# KM1M7CF14 register map
Vendor: Nuvoton Technology Corporation Japan; Series: KM1M7CF; File version: 1.0.3
CPU: CM7 r1p2, little endian, MPU, FPU, double-precision FPU, I-cache, D-cache, ITCM, DTCM, 4 interrupt priority bits
Registers are 32-bit, read-write, no defined reset value unless marked. A register's access mark holds for its fields unless they carry their own. Offsets are from the block's base; [hi:lo] are bit positions; {n}, {i} and the like mark numbered series; 'fields as' and 'values as' point back to an identical list.

## SIF23456 — Serial Interface 2-6
Base 0x40050200
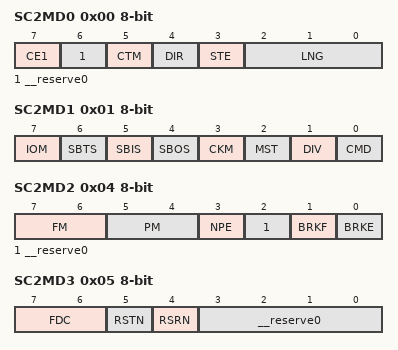
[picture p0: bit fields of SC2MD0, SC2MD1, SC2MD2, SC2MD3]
0x00 SC2MD0 8-bit — Serial 2 Mode Register 0
  [7] CE1 — Clock polarity selection [Clock-Synchronous]
  [6] __reserve0 — This bit must be set to "0".
  [5] CTM — Continuous communication mode selection [Clock-Synchronous]
  [4] DIR — Transfer first bit selection
  [3] STE — Start condition selection [Clock-Synchronous] (*1)
  [2:0] LNG — Transfer bit count [Clock-Synchronous] (*2)
0x01 SC2MD1 8-bit — Serial 2 Mode Register 1
  [7] IOM — Data input pin selection
  [6] SBTS — SBTn pin control
  [5] SBIS — SBIn(RXDn)/SBOn(TXDn) pin input control
  [4] SBOS — SBOn(TXDn) pin output control
  [3] CKM — Division selection of transfer clock [Clock-Synchronous]
  [2] MST — Master/salve communication selection [Clock-Synchronous]
  [1] DIV — Division value selection of transfer clock (*1)
  [0] CMD — Communication mode selection
0x04 SC2MD2 8-bit access per field — Serial 2 Mode Register 2
  [7:6] FM rw — The number of character bit and stop bit selection [UART]
  [5:4] PM rw — Parity bit function selection [UART]
  [3] NPE rw — Parity bit selection [UART]
  [2] __reserve0 rw — This bit must be set to "0".
  [1] BRKF ro — Break reception detection [UART]
  [0] BRKE rw — Break transmission control [UART]
0x05 SC2MD3 8-bit access per field — Serial 2 Mode Register 3
  [7:6] FDC rw — Output level selection after the final bit transmit (SBOn pin) [Clock-Synchronous]
  [5] RSTN rw — [Clock-Synchronous]
  [4] RSRN rw — [Clock-Synchronous]
  [3:0] __reserve0 ro — "0" is always read out.
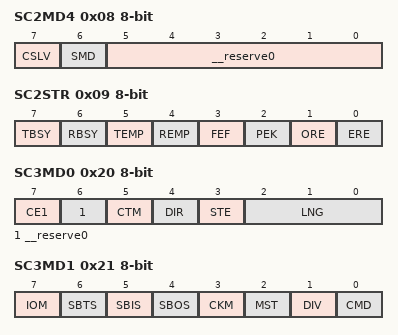
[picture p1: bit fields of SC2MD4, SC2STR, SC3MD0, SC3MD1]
0x08 SC2MD4 8-bit access per field — Serial 2 Mode Register 4
  [7] CSLV rw — SBCSn polarity selection
  [6] SMD rw — Clock-synchronous communication type selection
  [5:0] __reserve0 ro — "0" is always read out.
0x09 SC2STR 8-bit ro — Serial 2 Status Register
  [7] TBSY — Transmission busy detection
  [6] RBSY — Reception busy detection
  [5] TEMP — Transmission buffer empty
  [4] REMP — Reception buffer empty
  [3] FEF — Framing error detection [UART]
  [2] PEK — Parity error detection [UART]
  [1] ORE — Overrun error detection
  [0] ERE — Reception error detection
0x0C SC2RB 8-bit ro — Serial 2 Reception Data Buffer Register
  [7:0] RB — Reception data is read out.
0x10 SC2TB 8-bit — Serial 2 Transmission Data Buffer Register
  [7:0] TB — Set the transmission data or the dummy data.
0x20 SC3MD0 8-bit — Serial 3 Mode Register 0
  fields as SC2MD0
0x21 SC3MD1 8-bit — Serial 3 Mode Register 1
  fields as SC2MD1
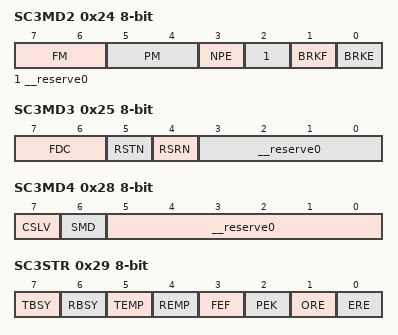
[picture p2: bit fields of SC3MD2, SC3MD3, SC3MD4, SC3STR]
0x24 SC3MD2 8-bit access per field — Serial 3 Mode Register 2
  fields as SC2MD2
0x25 SC3MD3 8-bit access per field — Serial 3 Mode Register 3
  fields as SC2MD3
0x28 SC3MD4 8-bit access per field — Serial 3 Mode Register 4
  fields as SC2MD4
0x29 SC3STR 8-bit ro — Serial 3 Status Register
  fields as SC2STR
0x2C SC3RB 8-bit ro — Serial 3 Reception Data Buffer Register
  [7:0] RB — Reception data is read out.
0x30 SC3TB 8-bit — Serial 3 Transmission Data Buffer Register
  [7:0] TB — Set the transmission data or the dummy data.
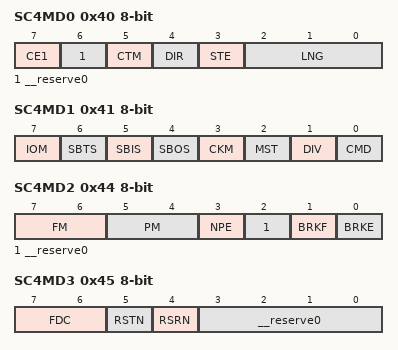
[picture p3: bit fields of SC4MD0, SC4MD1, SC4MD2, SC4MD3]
0x40 SC4MD0 8-bit — Serial 4 Mode Register 0
  fields as SC2MD0
0x41 SC4MD1 8-bit — Serial 4 Mode Register 1
  fields as SC2MD1
0x44 SC4MD2 8-bit access per field — Serial 4 Mode Register 2
  fields as SC2MD2
0x45 SC4MD3 8-bit access per field — Serial 4 Mode Register 3
  fields as SC2MD3
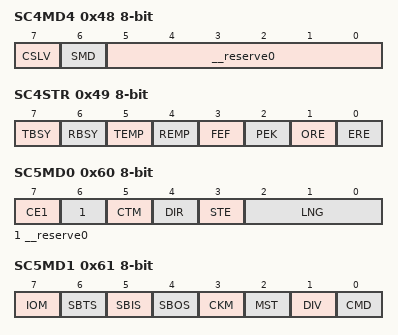
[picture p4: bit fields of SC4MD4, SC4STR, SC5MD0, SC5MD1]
0x48 SC4MD4 8-bit access per field — Serial 4 Mode Register 4
  fields as SC2MD4
0x49 SC4STR 8-bit ro — Serial 4 Status Register
  fields as SC2STR
0x4C SC4RB 8-bit ro — Serial 4 Reception Data Buffer Register
  [7:0] RB — Reception data is read out.
0x50 SC4TB 8-bit — Serial 4 Transmission Data Buffer Register
  [7:0] TB — Set the transmission data or the dummy data.
0x60 SC5MD0 8-bit — Serial 5 Mode Register 0
  fields as SC2MD0
0x61 SC5MD1 8-bit — Serial 5 Mode Register 1
  fields as SC2MD1
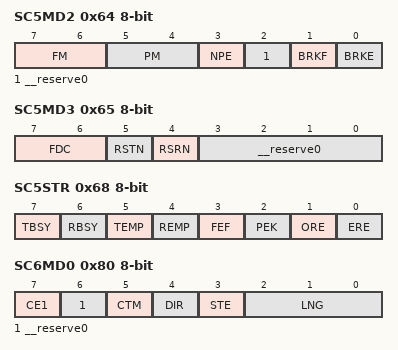
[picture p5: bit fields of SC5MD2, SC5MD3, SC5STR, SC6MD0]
0x64 SC5MD2 8-bit access per field — Serial 5 Mode Register 2
  fields as SC2MD2
0x65 SC5MD3 8-bit access per field — Serial 5 Mode Register 3
  fields as SC2MD3
0x68 SC5STR 8-bit ro — Serial 5 Status Register
  fields as SC2STR
0x6C SC5RB 8-bit ro — Serial 5 Reception Data Buffer Register
  [7:0] RB — Reception data is read out.
0x70 SC5TB 8-bit — Serial 5 Transmission Data Buffer Register
  [7:0] TB — Set the transmission data or the dummy data.
0x80 SC6MD0 8-bit — Serial 6 Mode Register 0
  fields as SC2MD0
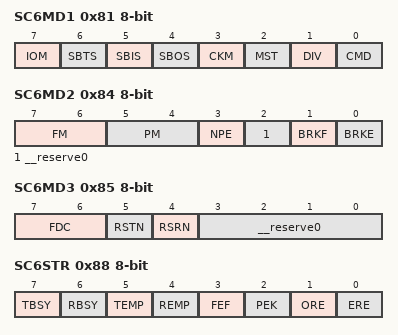
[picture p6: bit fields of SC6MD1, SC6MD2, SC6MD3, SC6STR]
0x81 SC6MD1 8-bit — Serial 6 Mode Register 1
  fields as SC2MD1
0x84 SC6MD2 8-bit access per field — Serial 6 Mode Register 2
  fields as SC2MD2
0x85 SC6MD3 8-bit access per field — Serial 6 Mode Register 3
  fields as SC2MD3
0x88 SC6STR 8-bit ro — Serial 6 Status Register
  fields as SC2STR
0x8C SC6RB 8-bit ro — Serial 6 Reception Data Buffer Register
  [7:0] RB — Reception data is read out.
0x90 SC6TB 8-bit — Serial 6 Transmission Data Buffer Register
  [7:0] TB — Set the transmission data or the dummy data.
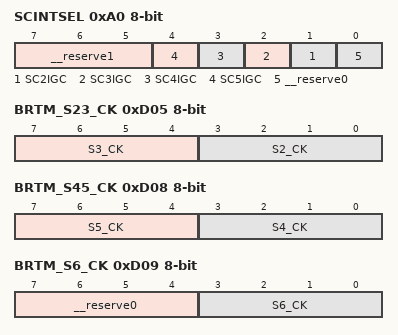
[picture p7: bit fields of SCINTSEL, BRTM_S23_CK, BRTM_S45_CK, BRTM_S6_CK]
0xA0 SCINTSEL 8-bit access per field — Clock Edge Interrupt Setting Register
  [7:5] __reserve1 ro — "0" is always read out.
  [n-1] SC{n}IGC rw (n=2..5) — Control of SBT{n} falling edge interrupt
  [0] __reserve0 ro — "0" is always read out.
0xD05 BRTM_S23_CK 8-bit — Baud Rate Timer 23 Count Clock Selection Register
  [7:4] S3_CK — Selection of count clock in baud rate timer 3
  [3:0] S2_CK — Selection of count clock in baud rate timer 2
0xD08 BRTM_S45_CK 8-bit — Baud Rate Timer 45 Count Clock Selection Register
  [7:4] S5_CK — Selection of count clock in baud rate timer 5
  [3:0] S4_CK — Selection of count clock in baud rate timer 4
0xD09 BRTM_S6_CK 8-bit — Baud Rate Timer 6 Count Clock Selection Register
  [7:4] __reserve0 — "0" is always read out.
  [3:0] S6_CK — Selection of count clock in baud rate timer 6
0xD14 BRTM_S2_OC 8-bit — Baud Rate Timer 2 Compare Register
  [7:0] Sn_OC — Set the value to be compared with the counter of baud rate timer n.
0xD15 BRTM_S3_OC 8-bit — Baud Rate Timer 3 Compare Register
  fields as BRTM_S2_OC
0xD18 BRTM_S4_OC 8-bit — Baud Rate Timer 4 Compare Register
  fields as BRTM_S2_OC
0xD19 BRTM_S5_OC 8-bit — Baud Rate Timer 5 Compare Register
  fields as BRTM_S2_OC
0xD1C BRTM_S6_OC 8-bit — Baud Rate Timer 6 Compare Register
  fields as BRTM_S2_OC
